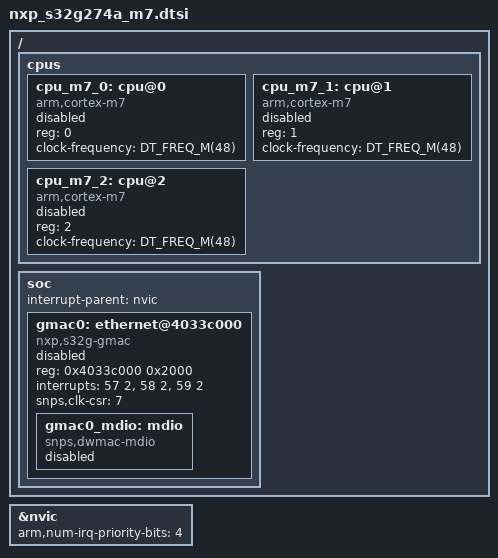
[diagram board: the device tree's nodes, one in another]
/*
 * Copyright The Zephyr Project Contributors
 *
 * SPDX-License-Identifier: Apache-2.0
 */

#include <arm/armv7-m.dtsi>
#include <nxp/s32/nxp_s32g274a.dtsi>
#include <freq.h>

/ {
	cpus {
		#address-cells = <1>;
		#size-cells = <0>;

		cpu_m7_0: cpu@0 {
			device_type = "cpu";
			compatible = "arm,cortex-m7";
			reg = <0>;
			clock-frequency = <DT_FREQ_M(48)>;
			status = "disabled";
		};

		cpu_m7_1: cpu@1 {
			device_type = "cpu";
			compatible = "arm,cortex-m7";
			reg = <1>;
			clock-frequency = <DT_FREQ_M(48)>;
			status = "disabled";
		};

		cpu_m7_2: cpu@2 {
			device_type = "cpu";
			compatible = "arm,cortex-m7";
			reg = <2>;
			clock-frequency = <DT_FREQ_M(48)>;
			status = "disabled";
		};
	};

	soc {
		interrupt-parent = <&nvic>;

		gmac0: ethernet@4033c000 {
			compatible = "nxp,s32g-gmac", "snps,dwmac";
			reg = <0x4033c000 0x2000>;
			interrupts = <57 2>, <58 2>, <59 2>;
			interrupt-names = "common", "tx", "rx";
			snps,clk-csr = <7>;
			status = "disabled";

			gmac0_mdio: mdio {
				compatible = "snps,dwmac-mdio";
				#address-cells = <1>;
				#size-cells = <0>;
				status = "disabled";
			};
		};
	};
};

&nvic {
	arm,num-irq-priority-bits = <4>;
};
